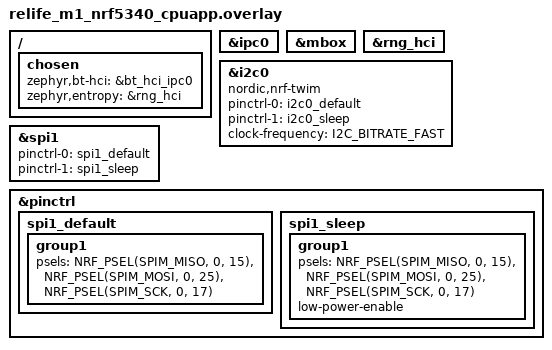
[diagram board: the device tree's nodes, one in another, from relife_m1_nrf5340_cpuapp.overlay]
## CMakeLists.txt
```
cmake_minimum_required(VERSION 3.20.0)
find_package(Zephyr REQUIRED HINTS $ENV{ZEPHYR_BASE})

project(ReLife_M1_V3)

string(TIMESTAMP RELIFE_BUILD_UNIX "%s" UTC)
configure_file(
    ${CMAKE_CURRENT_SOURCE_DIR}/src/relife_build_time.h.in
    ${CMAKE_CURRENT_BINARY_DIR}/generated/relife_build_time.h
    @ONLY
)

target_include_directories(app PRIVATE
    include
    include/bma400
    include/mlx90632
    src
    ${CMAKE_CURRENT_BINARY_DIR}/generated
)

target_sources(app PRIVATE
    src/main.c
    src/drivers/power/board_power.c
    src/drivers/fram/fram_cy15b108.c
    src/drivers/rv3028/rv3028_simple.c
    src/drivers/bma400/bma400_simple.c
    src/drivers/max30101/max30101_simple.c
    src/drivers/mlx90632/mlx90632_simple.c
    src/drivers/mlx90632/mlx90632_lib.c
    src/drivers/mlx90632/mlx90632_extended_meas.c
    src/shell_commands.c
    include/bma400/bma400.c
)

target_link_libraries(app PRIVATE m)
```

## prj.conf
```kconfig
CONFIG_USE_SEGGER_RTT=y
CONFIG_RTT_CONSOLE=y
CONFIG_PRINTK=y
CONFIG_SHELL=y
CONFIG_SHELL_BACKEND_RTT=y
CONFIG_SHELL_STACK_SIZE=4096
CONFIG_SHELL_PROMPT_RTT="relife> "
CONFIG_SHELL_VT100_COMMANDS=n
CONFIG_SHELL_CMDS=n
CONFIG_KERNEL_SHELL=n
CONFIG_DEVICE_SHELL=n
CONFIG_DEVMEM_SHELL=n
CONFIG_SHELL_LOG_BACKEND=y

CONFIG_LOG=y
CONFIG_LOG_MODE_DEFERRED=y
CONFIG_LOG_BACKEND_RTT=n
CONFIG_LOG_BACKEND_SHOW_COLOR=n
CONFIG_LOG_DEFAULT_LEVEL=3

CONFIG_GPIO=y
CONFIG_I2C=y
CONFIG_SPI=y

CONFIG_NEWLIB_LIBC=y
CONFIG_FPU=y

CONFIG_BT=y
CONFIG_BT_PERIPHERAL=y
CONFIG_BT_DEVICE_NAME="ReLife M1"
CONFIG_BT_DEVICE_APPEARANCE=833
CONFIG_BT_MAX_CONN=1
CONFIG_BT_PRIVACY=n
CONFIG_BT_GATT_DYNAMIC_DB=n

CONFIG_MBOX=y

CONFIG_MAIN_STACK_SIZE=8192
CONFIG_SYSTEM_WORKQUEUE_STACK_SIZE=4096
CONFIG_HEAP_MEM_POOL_SIZE=16384
```

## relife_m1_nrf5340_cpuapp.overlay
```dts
/ {
    chosen {
        zephyr,bt-hci = &bt_hci_ipc0;
        zephyr,entropy = &rng_hci;
    };
};

&ipc0 {
    status = "okay";
};

&mbox {
    status = "okay";
};

&rng_hci {
    status = "okay";
};

&i2c0 {
    compatible = "nordic,nrf-twim";
    status = "okay";
    pinctrl-0 = <&i2c0_default>;
    pinctrl-1 = <&i2c0_sleep>;
    pinctrl-names = "default", "sleep";
    clock-frequency = <I2C_BITRATE_FAST>;
};

&spi1 {
    status = "okay";
    pinctrl-0 = <&spi1_default>;
    pinctrl-1 = <&spi1_sleep>;
    pinctrl-names = "default", "sleep";
};

&pinctrl {
    spi1_default: spi1_default {
        group1 {
            psels = <NRF_PSEL(SPIM_MISO, 0, 15)>,
                    <NRF_PSEL(SPIM_MOSI, 0, 25)>,
                    <NRF_PSEL(SPIM_SCK, 0, 17)>;
        };
    };

    spi1_sleep: spi1_sleep {
        group1 {
            psels = <NRF_PSEL(SPIM_MISO, 0, 15)>,
                    <NRF_PSEL(SPIM_MOSI, 0, 25)>,
                    <NRF_PSEL(SPIM_SCK, 0, 17)>;
            low-power-enable;
        };
    };
};
```

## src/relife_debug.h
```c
#ifndef RELIFE_DEBUG_H
#define RELIFE_DEBUG_H

#include <stdbool.h>
#include <stdint.h>

#include "relife_protocol.h"

struct relife_bt_debug_state {
    bool connected;
    bool data_notify_enabled;
    bool status_notify_enabled;
};

int relife_debug_get_storage_meta(struct relife_storage_meta *meta);
int relife_debug_get_latest_record(struct relife_record_wire *record);
int relife_debug_get_record_by_id(uint32_t record_id, struct relife_record_wire *record);
void relife_debug_get_status(struct relife_status_wire *status);
void relife_debug_get_bt_state(struct relife_bt_debug_state *state);
bool relife_debug_get_measure_max_mode(void);
void relife_debug_set_measure_max_mode(bool enabled);

int relife_debug_read_rtc(uint32_t *unix_time, bool *ready, bool *valid_time);
int relife_debug_set_rtc(uint32_t unix_time);
int relife_debug_read_steps(uint32_t *steps_total, uint8_t *activity, bool *ready);
int relife_debug_read_skin_temp(int16_t *temp_centi_c, bool *ready);
int relife_debug_read_pulse(uint8_t *heart_rate_bpm, bool *hr_valid, uint8_t *spo2_percent, bool *spo2_valid,
                            bool *ready);

int relife_debug_force_sync(uint32_t after_id);
int relife_debug_abort_sync(void);

#endif
```

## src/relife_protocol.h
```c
#ifndef RELIFE_PROTOCOL_H
#define RELIFE_PROTOCOL_H

#include <stdint.h>

#include <zephyr/sys/util.h>

#define RELIFE_PROTOCOL_VERSION              3U
#define RELIFE_DEVICE_NAME                   "ReLife M1"

#define RELIFE_FRAM_CAPACITY                 1048576UL
#define RELIFE_FRAM_WRITE_POINTER_ADDR       0x00000UL
#define RELIFE_FRAM_METADATA_ADDR            0x00004UL
#define RELIFE_FRAM_RECORDS_ADDR             0x00040UL

#define RELIFE_STORAGE_MAGIC                 0x33464C52UL
#define RELIFE_STORAGE_VERSION               0x00030000UL

#define RELIFE_RECORD_SIZE                   20U
#define RELIFE_MAX_RECORDS                   ((RELIFE_FRAM_CAPACITY - RELIFE_FRAM_RECORDS_ADDR) / RELIFE_RECORD_SIZE)

#define RELIFE_FIRST_MEASUREMENT_DELAY_SEC   5U
#define RELIFE_PPG_CAPTURE_MS                8000U
#define RELIFE_SENSOR_STABILIZE_MS           500U
#define RELIFE_STEPS_ACTIVE_INTERVAL_SEC     60U
#define RELIFE_STEPS_IDLE_INTERVAL_SEC       300U
#define RELIFE_TEMP_FAST_INTERVAL_SEC        120U
#define RELIFE_TEMP_IDLE_INTERVAL_SEC        300U
#define RELIFE_TEMP_DELTA_CENTI_C            30
#define RELIFE_PPG_CONNECTED_VALID_INTERVAL_SEC   120U
#define RELIFE_PPG_CONNECTED_RETRY_INTERVAL_SEC   45U
#define RELIFE_PPG_IDLE_VALID_INTERVAL_SEC        300U
#define RELIFE_PPG_IDLE_RETRY_INTERVAL_SEC        120U

enum relife_opcode {
    RELIFE_OPCODE_GET_STATUS = 0x01,
    RELIFE_OPCODE_START_SYNC = 0x02,
    RELIFE_OPCODE_ACK_UP_TO  = 0x03,
    RELIFE_OPCODE_ABORT_SYNC = 0x04,
    RELIFE_OPCODE_RTC_SYNC   = 0x05,
};

enum relife_sync_state {
    RELIFE_SYNC_STATE_IDLE = 0,
    RELIFE_SYNC_STATE_SYNCING = 1,
    RELIFE_SYNC_STATE_WAITING_ACK = 2,
    RELIFE_SYNC_STATE_ERROR = 3,
};

enum relife_error_code {
    RELIFE_ERROR_NONE = 0,
    RELIFE_ERROR_FRAM = 1,
    RELIFE_ERROR_STORAGE = 2,
    RELIFE_ERROR_RTC = 3,
    RELIFE_ERROR_SENSOR = 4,
    RELIFE_ERROR_SYNC = 5,
    RELIFE_ERROR_PROTOCOL = 6,
};

enum relife_record_flags {
    RELIFE_FLAG_HR_VALID = BIT(0),
    RELIFE_FLAG_SPO2_VALID = BIT(1),
    RELIFE_FLAG_TEMP_VALID = BIT(2),
    RELIFE_FLAG_STEPS_VALID = BIT(3),
    RELIFE_FLAG_BATTERY_VALID = BIT(4),
    RELIFE_FLAG_RTC_VALID = BIT(5),
};

struct relife_command_wire {
    uint8_t opcode;
    uint8_t reserved[3];
    uint32_t value;
} __packed;

struct relife_record_wire {
    uint32_t record_id;
    uint32_t timestamp_unix;
    uint8_t heart_rate_bpm;
    uint8_t spo2_percent;
    int16_t skin_temp_centi_c;
    uint32_t steps_total;
    uint8_t battery_percent;
    uint8_t flags;
    uint16_t crc16;
} __packed;

struct relife_status_wire {
    uint8_t protocol_version;
    uint8_t state;
    uint8_t error_code;
    uint8_t reserved;
    uint32_t oldest_record_id;
    uint32_t newest_record_id;
    uint32_t last_confirmed_id;
    uint32_t snapshot_end_id;
} __packed;

struct relife_storage_meta {
    uint32_t magic;
    uint32_t version;
    uint32_t head_index;
    uint32_t tail_index;
    uint32_t count;
    uint32_t next_record_id;
    uint32_t last_confirmed_id;
    uint32_t last_rtc_sync_unix;
};

BUILD_ASSERT(sizeof(struct relife_command_wire) == 8, "Command packet must stay fixed");
BUILD_ASSERT(sizeof(struct relife_record_wire) == RELIFE_RECORD_SIZE, "Record packet must fit one ATT notify");
BUILD_ASSERT(sizeof(struct relife_status_wire) == 20, "Status packet must stay fixed");

#endif
```
